# STM32G474xx register map
File version: 1.4
CPU: CM4 r0p1, little endian, MPU, FPU, 4 interrupt priority bits
Registers are 32-bit, read-write, reset 0x0 unless marked. A register's access mark holds for its fields unless they carry their own. Offsets are from the block's base; [hi:lo] are bit positions; {n}, {i} and the like mark numbered series.

## DBGMCU — Debug support
Base 0xE0042000
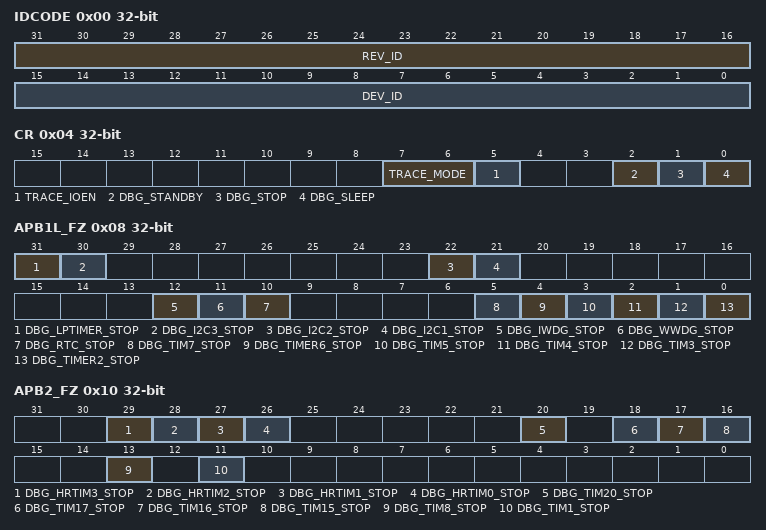
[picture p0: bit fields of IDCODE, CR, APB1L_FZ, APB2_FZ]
0x00 IDCODE ro — MCU Device ID Code Register
  [31:16] REV_ID — Revision Identifier
  [15:0] DEV_ID — Device Identifier
0x04 CR — Debug MCU Configuration Register
  [7:6] TRACE_MODE — Trace pin assignment control
  [5] TRACE_IOEN — Trace pin assignment control
  [2] DBG_STANDBY — Debug Standby Mode
  [1] DBG_STOP — Debug Stop Mode
  [0] DBG_SLEEP — Debug Sleep Mode
0x08 APB1L_FZ — APB Low Freeze Register 1
  [31] DBG_LPTIMER_STOP — LPTIM1 counter stopped when core is halted
  [30] DBG_I2C3_STOP — I2C3 SMBUS timeout mode stopped when core is halted
  [22] DBG_I2C2_STOP — I2C2 SMBUS timeout mode stopped when core is halted
  [21] DBG_I2C1_STOP — I2C1 SMBUS timeout mode stopped when core is halted
  [12] DBG_IWDG_STOP — Debug Independent Wachdog stopped when Core is halted
  [11] DBG_WWDG_STOP — Debug Window Wachdog stopped when Core is halted
  [10] DBG_RTC_STOP — Debug RTC stopped when Core is halted
  [5] DBG_TIM7_STOP — TIM7 counter stopped when core is halted
  [4] DBG_TIMER6_STOP — Debug Timer 6 stopped when Core is halted
  [3] DBG_TIM5_STOP — TIM5 counter stopped when core is halted
  [2] DBG_TIM4_STOP — TIM4 counter stopped when core is halted
  [1] DBG_TIM3_STOP — TIM3 counter stopped when core is halted
  [0] DBG_TIMER2_STOP — Debug Timer 2 stopped when Core is halted
0x0C APB1H_FZ — APB Low Freeze Register 2
  [1] DBG_I2C4_STOP
0x10 APB2_FZ — APB High Freeze Register
  [29] DBG_HRTIM3_STOP — DBG_HRTIM0_STOP
  [28] DBG_HRTIM2_STOP — DBG_HRTIM0_STOP
  [27] DBG_HRTIM1_STOP — DBG_HRTIM0_STOP
  [26] DBG_HRTIM0_STOP
  [20] DBG_TIM20_STOP — TIM20counter stopped when core is halted
  [18] DBG_TIM17_STOP — TIM17 counter stopped when core is halted
  [17] DBG_TIM16_STOP — TIM16 counter stopped when core is halted
  [16] DBG_TIM15_STOP — TIM15 counter stopped when core is halted
  [13] DBG_TIM8_STOP — TIM8 counter stopped when core is halted
  [11] DBG_TIM1_STOP — TIM1 counter stopped when core is halted

## RNG — Random number generator
Base 0x50060800
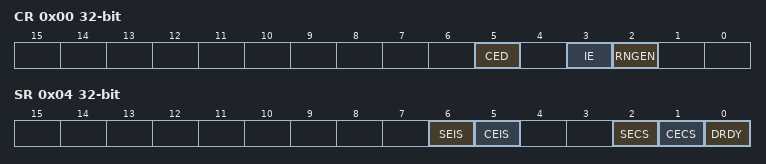
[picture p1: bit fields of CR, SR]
0x00 CR — control register
  [5] CED — Clock error detection
  [3] IE — Interrupt enable
  [2] RNGEN — Random number generator enable
0x04 SR access per field — status register
  [6] SEIS rw — Seed error interrupt status
  [5] CEIS rw — Clock error interrupt status
  [2] SECS ro — Seed error current status
  [1] CECS ro — Clock error current status
  [0] DRDY ro — Data ready
0x08 DR ro — data register
  [31:0] RNDATA — Random data

## GPIOA — General-purpose I/Os
Base 0x48000000
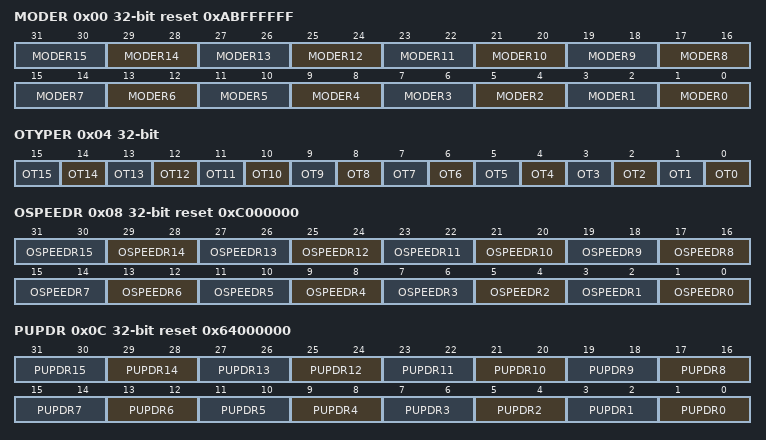
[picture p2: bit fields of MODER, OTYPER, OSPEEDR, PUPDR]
0x00 MODER reset 0xABFFFFFF — GPIO port mode register
  [2n+1:2n] MODER{n} (n=0..15) — Port x configuration bits (y = 0..15)
0x04 OTYPER — GPIO port output type register
  [n] OT{n} (n=0..15) — Port x configuration bits (y = 0..15)
0x08 OSPEEDR reset 0xC000000 — GPIO port output speed register
  [2n+1:2n] OSPEEDR{n} (n=0..15) — Port x configuration bits (y = 0..15)
0x0C PUPDR reset 0x64000000 — GPIO port pull-up/pull-down register
  [2n+1:2n] PUPDR{n} (n=0..15) — Port x configuration bits (y = 0..15)
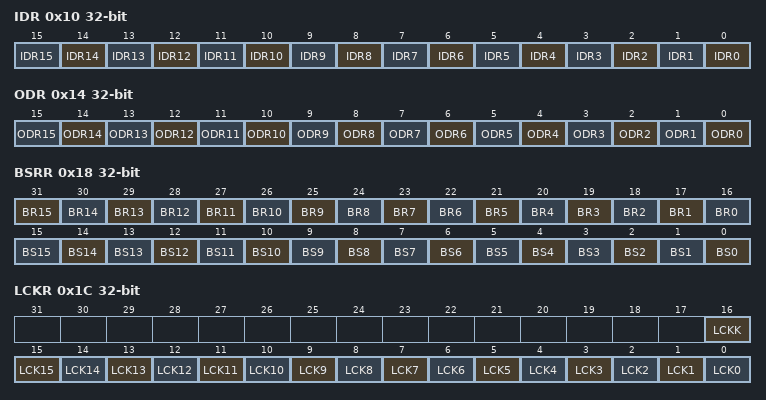
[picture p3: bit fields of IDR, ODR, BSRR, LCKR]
0x10 IDR ro — GPIO port input data register
  [n] IDR{n} (n=0..15) — Port input data (y = 0..15)
0x14 ODR — GPIO port output data register
  [n] ODR{n} (n=0..15) — Port output data (y = 0..15)
0x18 BSRR wo — GPIO port bit set/reset register
  [n+16] BR{n} (n=1..15) — Port x reset bit y (y = 0..15)
  [16] BR0 — Port x set bit y (y= 0..15)
  [n] BS{n} (n=0..15) — Port x set bit y (y= 0..15)
0x1C LCKR — GPIO port configuration lock register
  [16] LCKK — Port x lock bit y (y= 0..15)
  [n] LCK{n} (n=0..15) — Port x lock bit y (y= 0..15)
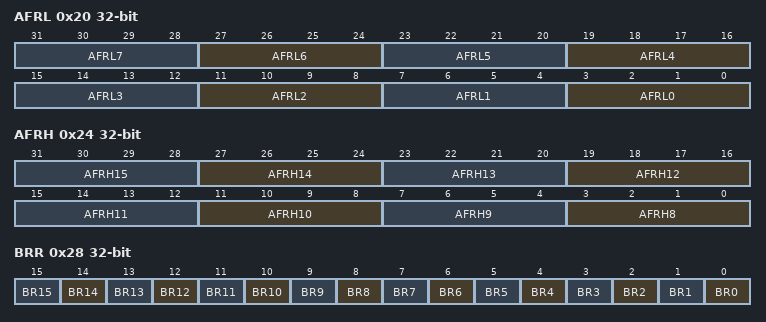
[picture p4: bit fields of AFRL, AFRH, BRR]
0x20 AFRL — GPIO alternate function low register
  [4n+3:4n] AFRL{n} (n=0..7) — Alternate function selection for port x bit y (y = 0..7)
0x24 AFRH — GPIO alternate function high register
  [4n-29:4n-32] AFRH{n} (n=8..15) — Alternate function selection for port x bit y (y = 8..15)
0x28 BRR wo — GPIO port bit reset register
  [n] BR{n} (n=0..15) — Port Reset bit

## GPIOB — General-purpose I/Os
Base 0x48000400
Registers as GPIOA; these are added or differ:
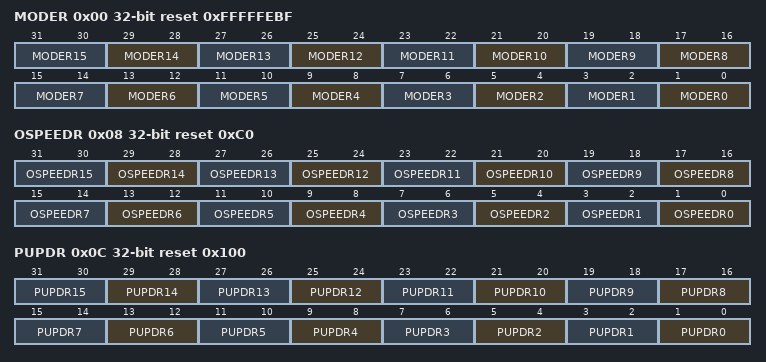
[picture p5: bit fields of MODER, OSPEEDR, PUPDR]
0x00 MODER reset 0xFFFFFEBF — GPIO port mode register
  [2n+1:2n] MODER{n} (n=0..15) — Port x configuration bits (y = 0..15)
0x08 OSPEEDR reset 0xC0 — GPIO port output speed register
  [2n+1:2n] OSPEEDR{n} (n=0..15) — Port x configuration bits (y = 0..15)
0x0C PUPDR reset 0x100 — GPIO port pull-up/pull-down register
  [2n+1:2n] PUPDR{n} (n=0..15) — Port x configuration bits (y = 0..15)

## GPIOC — General-purpose I/Os
Base 0x48000800
Same registers: GPIOD 0x48000C00, GPIOE 0x48001000, GPIOF 0x48001400, GPIOG 0x48001800
Registers as GPIOA; these are added or differ:
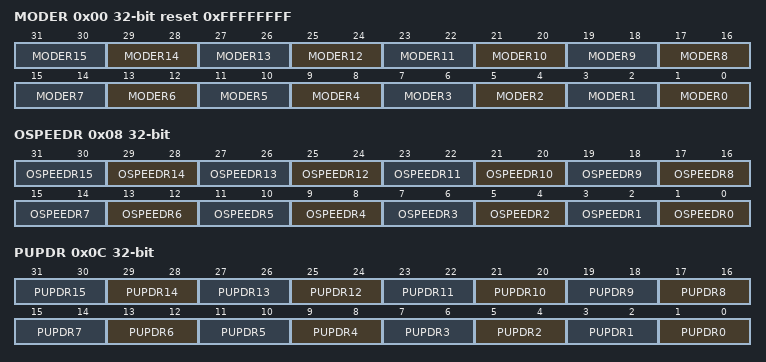
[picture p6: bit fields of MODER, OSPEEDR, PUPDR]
0x00 MODER reset 0xFFFFFFFF — GPIO port mode register
  [2n+1:2n] MODER{n} (n=0..15) — Port x configuration bits (y = 0..15)
0x08 OSPEEDR — GPIO port output speed register
  [2n+1:2n] OSPEEDR{n} (n=0..15) — Port x configuration bits (y = 0..15)
0x0C PUPDR — GPIO port pull-up/pull-down register
  [2n+1:2n] PUPDR{n} (n=0..15) — Port x configuration bits (y = 0..15)
